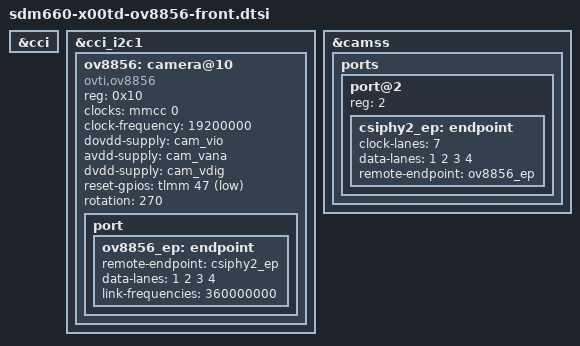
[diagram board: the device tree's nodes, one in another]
// SPDX-License-Identifier: GPL-2.0
/*
 * enjoys-os: front camera (OV8856) bring-up fragment for asus-x00td (sdm660).
 *
 * SCAFFOLD — grounded in the stock boot.img DTB + vendor camera_config.xml and
 * the mainline sdm630.dtsi camss/cci nodes. Values marked TODO still need to be
 * confirmed on the real device (camera bring-up is an on-device loop; QEMU
 * cannot emulate CAMSS).
 *
 * Front slot facts (from the stock ROM):
 *   sensor   : ov8856 (ov8856_chicony_front)   -> mainline driver: ovti,ov8856
 *   CSIPHY   : 2        CSID: 2        CCI master: 1 (cci_i2c1, GPIO38/39)
 *   lanes    : 4 (LaneMask 0x1F)      MountAngle: 270
 *   MCLK pin : TLMM GPIO33            RESET pin : TLMM GPIO47
 *   rails    : cam_vio (1.8V) cam_vana (2.8V) cam_vdig (~1.1V)
 */

&cci {
	status = "okay";
};

&cci_i2c1 {
	status = "okay";

	ov8856: camera@10 {
		compatible = "ovti,ov8856";
		reg = <0x10>;                 /* TODO: confirm I2C addr (0x10 vs 0x6c/2) */

		/* MCLK. Mainline ov8856 expects 19.2 MHz; stock DT used 24 MHz. */
		clocks = <&mmcc 0 /* TODO: sdm660 CAMSS cam mclk for this slot */>;
		clock-names = "xvclk";
		clock-frequency = <19200000>; /* TODO: try 24000000 if probe fails */

		/* Power rails — TODO: point at the x00td PMIC regulator phandles. */
		dovdd-supply = <&cam_vio>;    /* 1.8V I/O   */
		avdd-supply  = <&cam_vana>;   /* 2.8V analog */
		dvdd-supply  = <&cam_vdig>;   /* ~1.1V digital */

		reset-gpios = <&tlmm 47 GPIO_ACTIVE_LOW>;

		/* TODO: add pinctrl for the GPIO33 cam-mclk function. */
		/* pinctrl-names = "default"; pinctrl-0 = <&cam_mclk2_default>; */

		rotation = <270>;

		port {
			ov8856_ep: endpoint {
				remote-endpoint = <&csiphy2_ep>;
				data-lanes = <1 2 3 4>;
				/* OV8856 4-lane link freq; TODO: confirm. */
				link-frequencies = /bits/ 64 <360000000>;
			};
		};
	};
};

&camss {
	status = "okay";

	ports {
		/* CSIPHY2 receives the front sensor. */
		port@2 {
			reg = <2>;
			csiphy2_ep: endpoint {
				clock-lanes = <7>;
				data-lanes = <1 2 3 4>;
				remote-endpoint = <&ov8856_ep>;
			};
		};
	};
};
